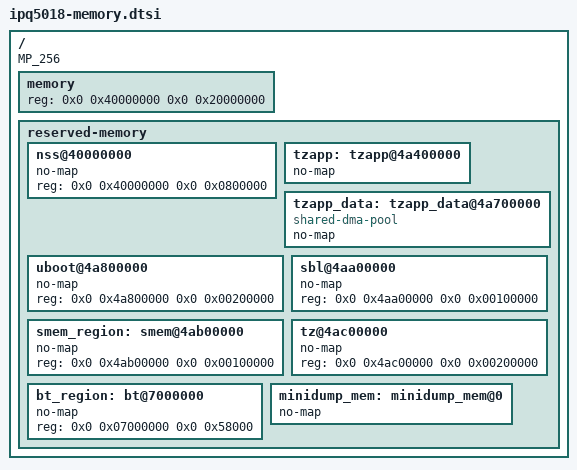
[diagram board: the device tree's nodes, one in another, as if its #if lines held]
/*
 * Copyright (c) 2016-2019, The Linux Foundation. All rights reserved.
 * Copyright (c) 2022, Qualcomm Innovation Center, Inc. All rights reserved.
 *
 * Permission to use, copy, modify, and/or distribute this software for any
 * purpose with or without fee is hereby granted, provided that the above
 * copyright notice and this permission notice appear in all copies.
 *
 * THE SOFTWARE IS PROVIDED "AS IS" AND THE AUTHOR DISCLAIMS ALL WARRANTIES
 * WITH REGARD TO THIS SOFTWARE INCLUDING ALL IMPLIED WARRANTIES OF
 * MERCHANTABILITY AND FITNESS. IN NO EVENT SHALL THE AUTHOR BE LIABLE FOR
 * ANY SPECIAL, DIRECT, INDIRECT, OR CONSEQUENTIAL DAMAGES OR ANY DAMAGES
 * WHATSOEVER RESULTING FROM LOSS OF USE, DATA OR PROFITS, WHETHER IN AN
 * ACTION OF CONTRACT, NEGLIGENCE OR OTHER TORTIOUS ACTION, ARISING OUT OF
 * OR IN CONNECTION WITH THE USE OR PERFORMANCE OF THIS SOFTWARE.
 */


/ {
	#ifdef __IPQ_MEM_PROFILE_256_MB__
	MP_256;
	#elif __IPQ_MEM_PROFILE_512_MB__
	MP_512;
	#else
	#endif

	memory {
		device_type = "memory";
		reg = <0x0 0x40000000 0x0 0x20000000>;
	};

	/*            256 MB Profile
	 * +=========+==============+========================+
	 * |        |              |                         |
	 * | Region | Start Offset |          Size           |
	 * |        |              |                         |
	 * +--------+--------------+-------------------------+
	 * |        |              |                         |
	 * |        |              |                         |
	 * |  NSS   |  0x40000000  |          8MB           |
	 * |        |              |                         |
	 * |        |              |                         |
	 * +--------+--------------+-------------------------+
	 * |        |              |                         |
	 * |        |              |                         |
	 * |        |              |                         |
	 * |        |              |                         |
	 * | Linux  |  0x40800000  | Depends on total memory |
	 * |        |              |                         |
	 * |        |              |                         |
	 * |        |              |                         |
	 * +        |              |                         |
	 * +--------+--------------+-------------------------+
	 * |        |              |                         |
	 * | uboot  |  0x4A800000  |           2MB           |
	 * |        |              |                         |
	 * +--------+--------------+-------------------------+
	 * |  SBL   |  0x4AA00000  |           1MB           |
	 * +--------+--------------+-------------------------+
	 * |  smem  |  0x4AB00000  |           1MB           |
	 * +--------+--------------+-------------------------+
	 * |        |              |                         |
	 * |   TZ   |  0x4AC00000  |           2MB           |
	 * |        |              |                         |
	 * +--------+--------------+-------------------------+
	 * |        |              |                         |
	 * |        |              |                         |
	 * |        |              |                         |
+	 * |   Q6   |  0x4B000000  | Refer target specific   |
+	 * | regions|              |  dts files              |
	 * +--------+--------------+-------------------------+
	 * |                                                 |
	 * |      Rest of the memory for Linux               |
	 * |                                                 |
	 * +=================================================+
	 */
	#ifdef __IPQ_MEM_PROFILE_256_MB__
	reserved-memory {
		#address-cells = <2>;
		#size-cells = <2>;
		ranges;

		nss@40000000 {
			no-map;
			reg = <0x0 0x40000000 0x0 0x0800000>;
		};

		tzapp:tzapp@4a400000 {	/* TZAPPS */
			no-map;
		};

		tzapp_data:tzapp_data@4a700000 {  /* TZAPP_DATA */
			compatible = "shared-dma-pool";
			no-map;
		};

		uboot@4a800000 {
			no-map;
			reg = <0x0 0x4a800000 0x0 0x00200000>;
		};

		sbl@4aa00000 {
			no-map;
			reg = <0x0 0x4aa00000 0x0 0x00100000>;
		};

		smem_region:smem@4ab00000 {
			no-map;
			reg = <0x0 0x4ab00000 0x0 0x00100000>;
		};

		tz@4ac00000 {	/* TZ */
			no-map;
			reg = <0x0 0x4ac00000 0x0 0x00200000>;
		};

		bt_region: bt@7000000 {
			no-map;
			reg = <0x0 0x07000000 0x0 0x58000>;
		};

		minidump_mem: minidump_mem@0 {
			no-map;
		};
	};
	/*                      512 MB Profile
	 * +=========+==============+========================+
	 * |        |              |                         |
	 * | Region | Start Offset |          Size           |
	 * |        |              |                         |
	 * +--------+--------------+-------------------------+
	 * |        |              |                         |
	 * |        |              |                         |
	 * |  NSS   |  0x40000000  |          16MB           |
	 * |        |              |                         |
	 * |        |              |                         |
	 * +--------+--------------+-------------------------+
	 * |        |              |                         |
	 * |        |              |                         |
	 * |        |              |                         |
	 * |        |              |                         |
	 * | Linux  |  0x41000000  | Depends on total memory |
	 * |        |              |                         |
	 * |        |              |                         |
	 * |        |              |                         |
	 * |        |              |                         |
	 * +--------+--------------+-------------------------+
	 * |        |              |                         |
	 * | uboot  |  0x4A800000  |           2MB           |
	 * |        |              |                         |
	 * +--------+--------------+-------------------------+
	 * |  SBL   |  0x4AA00000  |           1MB           |
	 * +--------+--------------+-------------------------+
	 * |  smem  |  0x4AB00000  |           1MB           |
	 * +--------+--------------+-------------------------+
	 * |        |              |                         |
	 * |   TZ   |  0x4AC00000  |           2MB           |
	 * |        |              |                         |
	 * +--------+--------------+-------------------------+
	 * |        |              |                         |
	 * |        |              |                         |
	 * |        |              |                         |
	 * |   Q6   |  0x4B000000  | Refer target specific   |
	 * | regions|              |  dts files              |
	 * |        |              |                         |
	 * +--------+--------------+-------------------------+
	 * |                                                 |
	 * |      Rest of the memory for Linux               |
	 * |                                                 |
	 * +=================================================+
	 */
	#else
	reserved-memory {
		#address-cells = <2>;
		#size-cells = <2>;
		ranges;

		nss@40000000 {
			no-map;
			reg = <0x0 0x40000000 0x0 0x01000000>;
		};

		tzapp:tzapp@4a400000 {	/* TZAPPS */
			no-map;
		};

		tzapp_data:tzapp_data@4a700000 {  /* TZAPP_DATA */
			compatible = "shared-dma-pool";
			no-map;
		};

		uboot@4a800000 {
			no-map;
			reg = <0x0 0x4a800000 0x0 0x00200000>;
		};

		sbl@4aa00000 {
			no-map;
			reg = <0x0 0x4aa00000 0x0 0x00100000>;
		};

		smem_region:smem@4ab00000 {
			no-map;
			reg = <0x0 0x4ab00000 0x0 0x00100000>;
		};

		tz@4ac00000 {	/* TZ */
			no-map;
			reg = <0x0 0x4ac00000 0x0 0x00200000>;
		};

		bt_region: bt@7000000 {
			no-map;
			reg = <0x0 0x07000000 0x0 0x58000>;
		};

		minidump_mem: minidump_mem@0 {
			no-map;
		};
	};
	#endif
};
